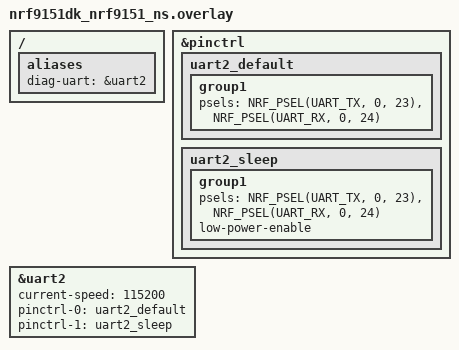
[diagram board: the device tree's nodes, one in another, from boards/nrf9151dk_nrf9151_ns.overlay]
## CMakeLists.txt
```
# SPDX-License-Identifier: Apache-2.0

cmake_minimum_required(VERSION 3.20.0)
find_package(Zephyr REQUIRED HINTS $ENV{ZEPHYR_BASE})
project(console_test)

target_sources(app PRIVATE src/main.c)
```

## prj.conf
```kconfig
# Minimal console-only smoke test -- see src/main.c and NOTES.md 2026-08-04.
# Deliberately does NOT include modem/LTE/MQTT/UART-receiver/flash-log --
# the point is to isolate whether gateway_9151's console problem is
# app-specific or a board/VCOM0-level issue.

CONFIG_GPIO=y

# CONFIG_SERIAL enables the general serial driver subsystem (all UART
# instances, not just uart0/console) -- also needed for uart2/diag_uart,
# see boards/nrf9151dk_nrf9151_ns.overlay.
CONFIG_SERIAL=y
CONFIG_CONSOLE=y
CONFIG_UART_CONSOLE=y
CONFIG_PRINTK=y

CONFIG_LOG=y
CONFIG_LOG_MODE_IMMEDIATE=y
CONFIG_LOG_DEFAULT_LEVEL=3

CONFIG_MAIN_STACK_SIZE=2048
```

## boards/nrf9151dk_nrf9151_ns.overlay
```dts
/*
 * Copyright (c) 2026
 *
 * SPDX-License-Identifier: Apache-2.0
 *
 * Second UART for the console mystery diagnostic (see NOTES.md 2026-08-04):
 * uart0 (console/VCOM0, P0.26/P0.27) is confirmed alive at the CPU/firmware
 * level (LED heartbeat, J-Link register reads) but produces zero output on
 * the DK's own USB port through every tool tried, including Nordic's own
 * nRF Connect Serial Terminal. uart0/uart1 are both wired through the DK's
 * Interface MCU (IMCU) to fixed VCOM channels -- there's no way to observe
 * them except via that same USB-CDC path, which is exactly the thing in
 * question.
 *
 * uart2 is a separate SiP UARTE instance, disabled by default on this board
 * (see zephyr/dts/arm/nordic/nrf91_peripherals.dtsi) and not wired to the
 * IMCU/USB at all -- routing it to free GPIOs (P0.23 TX, P0.24 RX, neither
 * used by anything else on this board, confirmed against
 * nrf9151dk_nrf9151_common.dtsi/-pinctrl.dtsi and the Arduino header's
 * gpio-map) tests the SiP's UART hardware directly via an external
 * USB-to-serial adapter, fully independent of the IMCU/VCOM path. If THIS
 * UART shows output but uart0 still doesn't, that confirms the fault is
 * specifically in the IMCU/VCOM0 path, not the SiP or this project's
 * firmware/toolchain.
 *
 * Wiring: P0.23 (TX, this board outputs here) -> adapter's RX,
 *         P0.24 (RX, this board listens here) -> adapter's TX (only needed
 *         if testing loopback/input, not required for a one-way heartbeat
 *         print), plus a shared GND between the DK and the adapter.
 */

&pinctrl {
	uart2_default: uart2_default {
		group1 {
			psels = <NRF_PSEL(UART_TX, 0, 23)>,
				<NRF_PSEL(UART_RX, 0, 24)>;
		};
	};

	uart2_sleep: uart2_sleep {
		group1 {
			psels = <NRF_PSEL(UART_TX, 0, 23)>,
				<NRF_PSEL(UART_RX, 0, 24)>;
			low-power-enable;
		};
	};
};

&uart2 {
	status = "okay";
	current-speed = <115200>;
	pinctrl-0 = <&uart2_default>;
	pinctrl-1 = <&uart2_sleep>;
	pinctrl-names = "default", "sleep";
};

/ {
	aliases {
		diag-uart = &uart2;
	};
};
```

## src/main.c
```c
/*
 * Copyright (c) 2026
 *
 * SPDX-License-Identifier: Apache-2.0
 *
 * Minimal console-only test: strips out everything gateway_9151 normally
 * does (modem, MQTT, UART receiver, flash log) down to just booting and
 * printing, to isolate whether gateway_9151's "zero serial output despite
 * a confirmed-healthy CPU" mystery (see NOTES.md 2026-08-04) is caused by
 * something in that app, or is a board/console-level problem independent
 * of any application code. Toggles LED1 every second as a visual heartbeat
 * that doesn't depend on the serial link at all -- if the LED blinks but
 * nothing appears on the console, that's strong evidence the app is fine
 * and the fault is specifically in the console UART/VCOM0 path.
 *
 * Also writes directly to uart2 (P0.23 TX / P0.24 RX, see
 * boards/nrf9151dk_nrf9151_ns.overlay) via uart_poll_out() -- deliberately
 * bypassing printk()/the console subsystem entirely, since uart0's own
 * console path is the thing under suspicion. uart2 isn't wired to the DK's
 * Interface MCU/USB at all, so seeing output here requires an external
 * USB-to-serial adapter, but it proves/disproves whether the SiP's UART
 * hardware itself is healthy, independent of the IMCU/VCOM path.
 */

#include <zephyr/kernel.h>
#include <zephyr/sys/printk.h>
#include <zephyr/logging/log.h>
#include <zephyr/drivers/gpio.h>
#include <zephyr/drivers/uart.h>

LOG_MODULE_REGISTER(console_test, LOG_LEVEL_INF);

static const struct gpio_dt_spec led = GPIO_DT_SPEC_GET_OR(DT_ALIAS(led0), gpios, { 0 });
static const struct device *const diag_uart = DEVICE_DT_GET_OR_NULL(DT_ALIAS(diag_uart));

static void diag_uart_print(const char *s)
{
	if (!diag_uart) {
		return;
	}

	for (; *s; s++) {
		uart_poll_out(diag_uart, *s);
	}
}

int main(void)
{
	printk("[CONSOLE_TEST] printk: booted\n");
	LOG_INF("LOG_INF: booted");

	bool led_ok = gpio_is_ready_dt(&led);

	if (led_ok) {
		gpio_pin_configure_dt(&led, GPIO_OUTPUT_INACTIVE);
	} else {
		printk("[CONSOLE_TEST] LED not ready, heartbeat will be console-only\n");
	}

	bool diag_uart_ok = diag_uart && device_is_ready(diag_uart);

	if (diag_uart_ok) {
		diag_uart_print("[DIAG_UART] uart2 (P0.23/P0.24) ready, booted\r\n");
	} else {
		printk("[CONSOLE_TEST] diag_uart (uart2) not ready\n");
	}

	uint32_t counter = 0;
	char line[48];

	while (1) {
		printk("[CONSOLE_TEST] printk tick %u\n", counter);
		LOG_INF("LOG_INF tick %u", counter);

		if (diag_uart_ok) {
			snprintk(line, sizeof(line), "[DIAG_UART] tick %u\r\n", counter);
			diag_uart_print(line);
		}

		if (led_ok) {
			gpio_pin_toggle_dt(&led);
		}

		counter++;
		k_sleep(K_SECONDS(1));
	}

	return 0;
}
```
